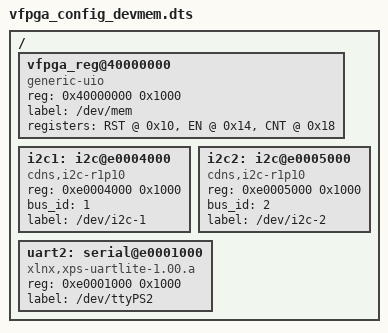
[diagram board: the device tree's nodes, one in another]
/dts-v1/;

/ {
    /* Node using /dev/mem to access FPGA registers */
    vfpga_reg@40000000 {
        compatible = "generic-uio";
        reg = <0x40000000 0x1000>;
        label = "/dev/mem";
        
        registers = 
            "RST @ 0x10",
            "EN  @ 0x14",
            "CNT @ 0x18";
    };

    i2c1: i2c@e0004000 {
        compatible = "cdns,i2c-r1p10";
        reg = <0xe0004000 0x1000>;
        bus_id = <1>;
        label = "/dev/i2c-1";
    };

    i2c2: i2c@e0005000 {
        compatible = "cdns,i2c-r1p10";
        reg = <0xe0005000 0x1000>;
        bus_id = <2>;
        label = "/dev/i2c-2";
    };

    uart2: serial@e0001000 {
        compatible = "xlnx,xps-uartlite-1.00.a";
        reg = <0xe0001000 0x1000>;
        label = "/dev/ttyPS2";
    };
};
